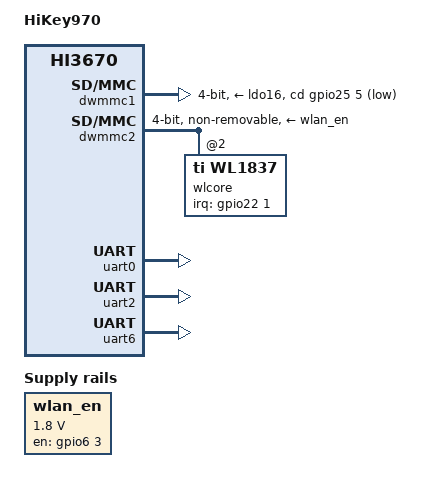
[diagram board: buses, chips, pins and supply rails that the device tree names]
/dts-v1/;
#include <dt-bindings/gpio/gpio.h>
#include "hi3670.dtsi"
#include "hikey970-pinctrl.dtsi"
#include "hikey970-pmic.dtsi"
/ {
	model = "HiKey970";
	compatible = "hisilicon,hi3670-hikey970", "hisilicon,hi3670";
	aliases {
		mshc1 = &dwmmc1;
		mshc2 = &dwmmc2;
		serial0 = &uart0;
		serial1 = &uart1;
		serial2 = &uart2;
		serial3 = &uart3;
		serial4 = &uart4;
		serial5 = &uart5;
		serial6 = &uart6;        
	};
	chosen {
		stdout-path = "serial6:115200n8";
	};
	memory@0 {
		device_type = "memory";
		reg = <0x0 0x0 0x0 0x0>;
	};
	wlan_en: wlan-en-1-8v {
		compatible = "regulator-fixed";
		regulator-name = "wlan-en-regulator";
		regulator-min-microvolt = <1800000>;
		regulator-max-microvolt = <1800000>;
		gpio = <&gpio6 3 0>;
		startup-delay-us = <70000>;
		enable-active-high;
	};
};
&gpio0 {
	gpio-line-names =
		"",
		"TP901",  
		"",
		"GPIO_003_USB_HUB_RESET_N",
		"NC",
		"[AP_GPS_REF_CLK]",
		"[I2C3_SCL]",
		"[I2C3_SDA]";
};
&gpio1 {
	gpio-line-names =
		"[UART0_CTS]",  
		"[UART0_RTS]",  
		"[UART0_TXD]",  
		"[UART0_RXD]",  
		"[USER_LED5]",
		"GPIO-I",  
		"[USER_LED3]",
		"[USER_LED4]";
};
&gpio2 {
	gpio-line-names =
		"GPIO-G",  
		"[CSI0_MCLK]",  
		"[CSI1_MCLK]",  
		"GPIO_019_BT_ACTIVE",
		"[I2C2_SCL]",  
		"[I2C2_SDA]",  
		"[I2C3_SCL]",  
		"[I2C3_SDA]";  
};
&gpio3 {
	gpio-line-names =
		"GPIO_024_WIFI_ACTIVE",
		"GPIO_025_PERST_M.2",
		"[I2C4_SCL]",
		"[I2C4_SDA]",
		"NC",
		"GPIO-H",  
		"[USER_LED1]",
		"GPIO-L";  
};
&gpio4 {
	gpio-line-names =
		"GPIO-K",  
		"GPIO_033_PMU1_EN",
		"GPIO_034_USBSW_SEL",
		"[SD_DAT1]",  
		"[SD_DAT2]",  
		"[UART1_RXD]",  
		"[UART1_TXD]",  
		"[SOC_GPS_UART3_CTS_N]";  
};
&gpio5 {
	gpio-line-names =
		"[SOC_GPS_UART3_RTS_N]",  
		"[SOC_GPS_UART3_RXD]",  
		"[SOC_GPS_UART3_TXD]",  
		"[SOC_BT_UART4_CTS_N]",
		"[SOC_BT_UART4_RTS_N]",
		"[SOC_BT_UART4_RXD]",
		"[SOC_BT_UART4_TXD]",
		"NC";
};
&gpio6 {
	gpio-line-names =
		"NC",
		"GPIO_049_USER_LED6",
		"GPIO_050_CAN_RST",
		"GPIO_051_WIFI_EN",
		"GPIO-D",  
		"GPIO-J",  
		"GPIO_054_BT_EN",
		"[GPIO_055_SEL]";
};
&gpio7 {
	gpio-line-names =
		"[PCIE_PERST_L]", "NC", "NC", "NC", "NC", "NC", "NC", "NC";
};
&gpio8 {
	gpio-line-names = "NC", "NC", "NC", "NC", "NC", "NC", "NC", "NC";
};
&gpio9 {
	gpio-line-names = "NC", "NC", "NC", "NC", "NC", "NC", "NC", "NC";
};
&gpio10 {
	gpio-line-names = "NC", "NC", "NC", "NC", "NC", "NC", "NC", "NC";
};
&gpio11 {
	gpio-line-names = "NC", "NC", "NC", "NC", "NC", "NC", "NC", "NC";
};
&gpio12 {
	gpio-line-names = "NC", "", "", "", "", "", "", "";
};
&gpio13 {
	gpio-line-names = "", "", "", "", "", "", "", "";
};
&gpio14 {
	gpio-line-names = "", "", "", "", "", "", "", "";
};
&gpio15 {
	gpio-line-names = "", "", "", "", "", "", "", "";
};
&gpio16 {
	gpio-line-names =
		"[WL_SDIO_CLK]",
		"[WL_SDIO_CMD]",
		"[WL_SDIO_DATA0]",
		"[WL_SDIO_DATA1]",
		"[WL_SDIO_DATA2]",
		"[WL_SDIO_DATA3]",
		"[ETH_ISOLATE]",
		"NC";
};
&gpio17 {
	gpio-line-names =
		"[MINI1CLK_EN]", "NC", "", "", "", "", "", "";
};
&gpio18 {
	gpio-line-names =
		"[SPI1_SCLK]",  
		"[SPI1_DIN]",  
		"[SPI1_DOUT]",  
		"[SPI1_CS]",  
		"[POWER_INT_N]",
		"[CDMA_GPS_SYNC]",
		"GPIO_150_PEX_INTA",
		"GPIO_151_CAN_INT";
};
&gpio19 {
	gpio-line-names = "", "", "", "", "", "", "", "";
};
&gpio20 {
	gpio-line-names =
		"[SD_CLK]",
		"[SD_CMD]",
		"[SD_DATA0]",
		"[SD_DATA1]",
		"[SD_DATA2]",
		"[SD_DATA3]",
		"GPIO_166_ETHCLK_EN",
		"GPIO_167_USER_LED2";
};
&gpio21 {
	gpio-line-names =
		"GPIO_168_GPS_EN",
		"GPIO-C",  
		"GPIO-E",  
		"GPIO-B",  
		"", "", "", "", "";
};
&gpio22 {
	gpio-line-names =
		"[PMU_PWR_HOLD]",
		"GPIO_177_WL_WAKEUP_AP",
		"[JTAG_TCK]",
		"[JTAG_TMS]",
		"[JTAG_TDI]",
		"[JTAG_TMS]",
		"GPIO_182_FATAL_ERR",
		"NC";
};
&gpio23 {
	gpio-line-names =
		"GPIO_184_JTAG_SEL",
		"GPIO-F",  
		"[I2C0_SCL]",  
		"[I2C0_SDA]",  
		"[GPIO_188_I2C1_SCL]",  
		"[GPIO_189_I2C1_SDA]",  
		"[I2C1_SCL]",  
		"[I2C2_SDA]";  
};
&gpio24 {
	gpio-line-names =
		"[SD_LED]",
		"NC",
		"[PCM_DI]",  
		"[PCM_DO]",  
		"[PCM_CLK]",  
		"[PCM_FS]",  
		"",
		"[I2S2_DO]";
};
&gpio25 {
	gpio-line-names =
		"[I2S2_XCLK]",
		"[I2S2_XFS]",
		"GPIO_202_PERST_ETH",
		"GPIO_203_PWRON_DET",
		"GPIO_204_PMU1_IRQ_N",
		"GPIO_205_SD_DET",
		"GPIO_206_GPS_MOTION_INT",
		"GPIO_207_HDMI_SEL";
};
&gpio26 {
	gpio-line-names =
		"GPIO-A",  
		"GPIO_209_VBUS_TYPEC",
		"NC",
		"NC",
		"NC",
		"[SPI0_SCLK]",  
		"[SPI0_DIN]",  
		"[SPI0_DOUT]";  
};
&gpio27 {
	gpio-line-names =
		"[SPI0_CS]",  
		"GPIO_217_HDMI_PD",
		"GPIO_218_GPS_WAKEUP_AP",
		"GPIO_219_M.2CLK_EN",
		"GPIO_220_PERST_MINI",
		"GPIO_221_CC_INT",
		"[PCIE_CLKREQ_L]",
		"NC";
};
&gpio28 {
	gpio-line-names =
		"[PMU0_INT]",
		"[SPMI_DATA]",
		"[SPMI_CLK]",
		"[CAN_SPI_CLK]",
		"[CAN_SPI_DI]",
		"[CAN_SPI_DO]",
		"[CAN_SPI_CS]",
		"GPIO_231_HDMI_INT";
};
&dwmmc1 {
	bus-width = <0x4>;
	sd-uhs-sdr12;
	sd-uhs-sdr25;
	sd-uhs-sdr50;
	sd-uhs-sdr104;
	cap-sd-highspeed;
	disable-wp;
	cd-inverted;
	cd-gpios = <&gpio25 5 GPIO_ACTIVE_HIGH>;
	pinctrl-names = "default";
	pinctrl-0 = <&sd_pmx_func
		     &sd_clk_cfg_func
		     &sd_cfg_func>;
	vmmc-supply = <&ldo16>;
	vqmmc-supply = <&ldo9>;
	status = "okay";
};
&dwmmc2 {  
	bus-width = <0x4>;
	non-removable;
	broken-cd;
	cap-power-off-card;
	pinctrl-names = "default";
	pinctrl-0 = <&sdio_pmx_func
		     &sdio_clk_cfg_func
		     &sdio_cfg_func>;
	vmmc-supply = <&wlan_en>;
	status = "okay";
	wlcore: wlcore@2 {
		compatible = "ti,wl1837";
		reg = <2>;       
		interrupt-parent = <&gpio22>;
		interrupts = <1 IRQ_TYPE_EDGE_RISING>;
	};
};
&uart0 {
	label = "HS-UART0";
	status = "okay";
};
&uart2 {
	label = "LS-UART0";
	status = "okay";
};
&uart6 {
	label = "LS-UART1";
	status = "okay";
};
